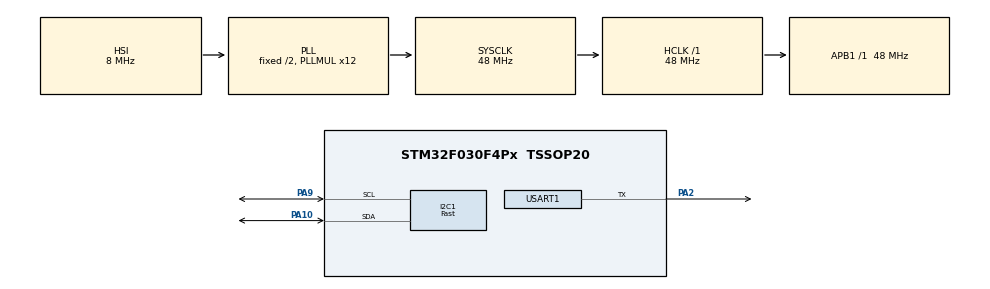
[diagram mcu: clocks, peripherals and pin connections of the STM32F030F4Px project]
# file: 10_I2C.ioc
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I2C1.Analog_Filter=I2C_ANALOGFILTER_DISABLE
I2C1.I2C_Speed_Mode=I2C_Fast
I2C1.Timing=0x0000020C
Mcu.Family=STM32F0
Mcu.Name=STM32F030F4Px
Mcu.Package=TSSOP20
PA10.Mode=I2C
PA10.Signal=I2C1_SDA
PA13.Mode=Serial_Wire
PA13.Signal=SYS_SWDIO
PA14.Mode=Serial_Wire
PA14.Signal=SYS_SWCLK
PA2.Mode=Half_duplex(single_wire_mode)
PA2.Signal=USART1_TX
PA9.Mode=I2C
PA9.Signal=I2C1_SCL
ProjectManager.HeapSize=0x200
ProjectManager.StackSize=0x400
ProjectManager.TargetToolchain=TrueSTUDIO
RCC.AHBFreq_Value=48000000
RCC.APB1Freq_Value=48000000
RCC.APB1TimFreq_Value=48000000
RCC.HCLKFreq_Value=48000000
RCC.PLLMUL=RCC_PLL_MUL12
RCC.SYSCLKFreq_VALUE=48000000
RCC.SYSCLKSource=RCC_SYSCLKSOURCE_PLLCLK
USART1.Mode=MODE_TX
USART1.VirtualMode-Half_duplex(single_wire_mode)=VM_ASYNC
board=10_I2C

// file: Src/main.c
/**
  ******************************************************************************
  * File Name          : main.c
  * Description        : Main program body
  ******************************************************************************
  ** This notice applies to any and all portions of this file
  * that are not between comment pairs USER CODE BEGIN and
  * USER CODE END. Other portions of this file, whether
  * inserted by the user or by software development tools
  * are owned by their respective copyright owners.
  *
  * COPYRIGHT(c) 2018 STMicroelectronics
  *
  * Redistribution and use in source and binary forms, with or without modification,
  * are permitted provided that the following conditions are met:
  *   1. Redistributions of source code must retain the above copyright notice,
  *      this list of conditions and the following disclaimer.
  *   2. Redistributions in binary form must reproduce the above copyright notice,
  *      this list of conditions and the following disclaimer in the documentation
  *      and/or other materials provided with the distribution.
  *   3. Neither the name of STMicroelectronics nor the names of its contributors
  *      may be used to endorse or promote products derived from this software
  *      without specific prior written permission.
  *
  * THIS SOFTWARE IS PROVIDED BY THE COPYRIGHT HOLDERS AND CONTRIBUTORS "AS IS"
  * AND ANY EXPRESS OR IMPLIED WARRANTIES, INCLUDING, BUT NOT LIMITED TO, THE
  * IMPLIED WARRANTIES OF MERCHANTABILITY AND FITNESS FOR A PARTICULAR PURPOSE ARE
  * DISCLAIMED. IN NO EVENT SHALL THE COPYRIGHT HOLDER OR CONTRIBUTORS BE LIABLE
  * FOR ANY DIRECT, INDIRECT, INCIDENTAL, SPECIAL, EXEMPLARY, OR CONSEQUENTIAL
  * DAMAGES (INCLUDING, BUT NOT LIMITED TO, PROCUREMENT OF SUBSTITUTE GOODS OR
  * SERVICES; LOSS OF USE, DATA, OR PROFITS; OR BUSINESS INTERRUPTION) HOWEVER
  * CAUSED AND ON ANY THEORY OF LIABILITY, WHETHER IN CONTRACT, STRICT LIABILITY,
  * OR TORT (INCLUDING NEGLIGENCE OR OTHERWISE) ARISING IN ANY WAY OUT OF THE USE
  * OF THIS SOFTWARE, EVEN IF ADVISED OF THE POSSIBILITY OF SUCH DAMAGE.
  *
  ******************************************************************************
  */
#include "main.h"
#include "stm32f0xx_hal.h"

/* USER CODE BEGIN Includes */
#include <string.h>
#include <stdio.h>
#include <stdlib.h>

/* USER CODE END Includes */

I2C_HandleTypeDef hi2c1;

UART_HandleTypeDef huart1;

/* USER CODE BEGIN PV */
/* Private variables ---------------------------------------------------------*/

/* USER CODE END PV */

void SystemClock_Config(void);
static void MX_GPIO_Init(void);
static void MX_I2C1_Init(void);
static void MX_USART1_UART_Init(void);

/* USER CODE BEGIN PFP */
/* Private function prototypes -----------------------------------------------*/
HAL_StatusTypeDef Write_To_24LCxx(I2C_HandleTypeDef *hi2c, uint16_t DevAddress, uint16_t MemAddress, uint8_t *pData, uint16_t len);
HAL_StatusTypeDef Read_From_24LCxx(I2C_HandleTypeDef *hi2c, uint16_t DevAddress, uint16_t MemAddress, uint8_t *pData, uint16_t len);

/* USER CODE END PFP */

int main(void)
{

  /* MCU Configuration----------------------------------------------------------*/

  /* Reset of all peripherals, Initializes the Flash interface and the Systick. */
  HAL_Init();

  /* Configure the system clock */
  SystemClock_Config();

  /* Initialize all configured peripherals */
  MX_GPIO_Init();
  MX_I2C1_Init();
  MX_USART1_UART_Init();

  /* USER CODE BEGIN 2 */

  // message for UART
  char msg[30];

  // Array for Write Message
  const char wmsg[] ="Hello I2C";

  // Array for Read Message, note must be exact size of Write Message
  char rmsg[10];

  /* USER CODE END 2 */

  /* Infinite loop */
  while (1)
  {

  /* USER CODE BEGIN 3 */
	 Write_To_24LCxx(&hi2c1, 0x50, 0x00, (uint8_t*)wmsg, strlen(wmsg)+1);
	 Read_From_24LCxx(&hi2c1, 0x50, 0x00, (uint8_t*)rmsg, strlen(wmsg)+1);

	 if(strcmp(wmsg, rmsg) == 0){
		 sprintf(msg, "Write Success!\n");
		 HAL_UART_Transmit(&huart1, (uint8_t*)msg, strlen(msg), HAL_MAX_DELAY);
		 sprintf(msg, "%s\n", rmsg);
		 HAL_UART_Transmit(&huart1, (uint8_t*)msg, strlen(msg), HAL_MAX_DELAY);
		 HAL_Delay(10000);
	 }

	 else
	 {
		sprintf(msg, "Write Failed, Read: %s\n", rmsg);
		HAL_UART_Transmit(&huart1, (uint8_t*)msg, strlen(msg), HAL_MAX_DELAY);
		HAL_Delay(10000);
	 }

  }
  /* USER CODE END 3 */

}

/** System Clock Configuration
*/
void SystemClock_Config(void)
{

  RCC_OscInitTypeDef RCC_OscInitStruct;
  RCC_ClkInitTypeDef RCC_ClkInitStruct;
  RCC_PeriphCLKInitTypeDef PeriphClkInit;

    /**Initializes the CPU, AHB and APB busses clocks
    */
  RCC_OscInitStruct.OscillatorType = RCC_OSCILLATORTYPE_HSI;
  RCC_OscInitStruct.HSIState = RCC_HSI_ON;
  RCC_OscInitStruct.HSICalibrationValue = 16;
  RCC_OscInitStruct.PLL.PLLState = RCC_PLL_ON;
  RCC_OscInitStruct.PLL.PLLSource = RCC_PLLSOURCE_HSI;
  RCC_OscInitStruct.PLL.PLLMUL = RCC_PLL_MUL12;
  RCC_OscInitStruct.PLL.PREDIV = RCC_PREDIV_DIV1;
  if (HAL_RCC_OscConfig(&RCC_OscInitStruct) != HAL_OK)
  {
    _Error_Handler(__FILE__, __LINE__);
  }

    /**Initializes the CPU, AHB and APB busses clocks
    */
  RCC_ClkInitStruct.ClockType = RCC_CLOCKTYPE_HCLK|RCC_CLOCKTYPE_SYSCLK
                              |RCC_CLOCKTYPE_PCLK1;
  RCC_ClkInitStruct.SYSCLKSource = RCC_SYSCLKSOURCE_PLLCLK;
  RCC_ClkInitStruct.AHBCLKDivider = RCC_SYSCLK_DIV1;
  RCC_ClkInitStruct.APB1CLKDivider = RCC_HCLK_DIV1;

  if (HAL_RCC_ClockConfig(&RCC_ClkInitStruct, FLASH_LATENCY_1) != HAL_OK)
  {
    _Error_Handler(__FILE__, __LINE__);
  }

  PeriphClkInit.PeriphClockSelection = RCC_PERIPHCLK_USART1|RCC_PERIPHCLK_I2C1;
  PeriphClkInit.Usart1ClockSelection = RCC_USART1CLKSOURCE_PCLK1;
  PeriphClkInit.I2c1ClockSelection = RCC_I2C1CLKSOURCE_HSI;
  if (HAL_RCCEx_PeriphCLKConfig(&PeriphClkInit) != HAL_OK)
  {
    _Error_Handler(__FILE__, __LINE__);
  }

    /**Configure the Systick interrupt time
    */
  HAL_SYSTICK_Config(HAL_RCC_GetHCLKFreq()/1000);

    /**Configure the Systick
    */
  HAL_SYSTICK_CLKSourceConfig(SYSTICK_CLKSOURCE_HCLK);

  /* SysTick_IRQn interrupt configuration */
  HAL_NVIC_SetPriority(SysTick_IRQn, 0, 0);
}

/* I2C1 init function */
static void MX_I2C1_Init(void)
{

  hi2c1.Instance = I2C1;
  hi2c1.Init.Timing = 0x0000020C;
  hi2c1.Init.OwnAddress1 = 0;
  hi2c1.Init.AddressingMode = I2C_ADDRESSINGMODE_7BIT;
  hi2c1.Init.DualAddressMode = I2C_DUALADDRESS_DISABLE;
  hi2c1.Init.OwnAddress2 = 0;
  hi2c1.Init.OwnAddress2Masks = I2C_OA2_NOMASK;
  hi2c1.Init.GeneralCallMode = I2C_GENERALCALL_DISABLE;
  hi2c1.Init.NoStretchMode = I2C_NOSTRETCH_DISABLE;
  if (HAL_I2C_Init(&hi2c1) != HAL_OK)
  {
    _Error_Handler(__FILE__, __LINE__);
  }

    /**Configure Analogue filter
    */
  if (HAL_I2CEx_ConfigAnalogFilter(&hi2c1, I2C_ANALOGFILTER_DISABLE) != HAL_OK)
  {
    _Error_Handler(__FILE__, __LINE__);
  }

    /**Configure Digital filter
    */
  if (HAL_I2CEx_ConfigDigitalFilter(&hi2c1, 0) != HAL_OK)
  {
    _Error_Handler(__FILE__, __LINE__);
  }

}

/* USART1 init function */
static void MX_USART1_UART_Init(void)
{

  huart1.Instance = USART1;
  huart1.Init.BaudRate = 38400;
  huart1.Init.WordLength = UART_WORDLENGTH_8B;
  huart1.Init.StopBits = UART_STOPBITS_1;
  huart1.Init.Parity = UART_PARITY_NONE;
  huart1.Init.Mode = UART_MODE_TX;
  huart1.Init.HwFlowCtl = UART_HWCONTROL_NONE;
  huart1.Init.OverSampling = UART_OVERSAMPLING_16;
  huart1.Init.OneBitSampling = UART_ONE_BIT_SAMPLE_DISABLE;
  huart1.AdvancedInit.AdvFeatureInit = UART_ADVFEATURE_NO_INIT;
  if (HAL_HalfDuplex_Init(&huart1) != HAL_OK)
  {
    _Error_Handler(__FILE__, __LINE__);
  }

}

/** Configure pins as
        * Analog
        * Input
        * Output
        * EVENT_OUT
        * EXTI
*/
static void MX_GPIO_Init(void)
{

  /* GPIO Ports Clock Enable */
  __HAL_RCC_GPIOA_CLK_ENABLE();

}

/* USER CODE BEGIN 4 */

HAL_StatusTypeDef Read_From_24LCxx(I2C_HandleTypeDef *hi2c, uint16_t DevAddress, uint16_t MemAddress, uint8_t *pData, uint16_t len) {
  HAL_StatusTypeDef returnValue;
  uint8_t addr[2];

  /* We compute the MSB and LSB parts of the memory address */
  addr[0] = (uint8_t) ((MemAddress & 0xFF00) >> 8);
  addr[1] = (uint8_t) (MemAddress & 0xFF);

  /* First we send the memory location address where start reading data */
  returnValue = HAL_I2C_Master_Transmit(hi2c, DevAddress, addr, 2, HAL_MAX_DELAY);
  if(returnValue != HAL_OK)
    return returnValue;

  /* Next we can retrieve the data from EEPROM */
  returnValue = HAL_I2C_Master_Receive(hi2c, DevAddress, pData, len, HAL_MAX_DELAY);

  return returnValue;
}

HAL_StatusTypeDef Write_To_24LCxx(I2C_HandleTypeDef *hi2c, uint16_t DevAddress, uint16_t MemAddress, uint8_t *pData, uint16_t len) {
  HAL_StatusTypeDef returnValue;
  uint8_t *data;

  /* First we allocate a temporary buffer to store the destination memory
   * address and the data to store */
  data = (uint8_t*)malloc(sizeof(uint8_t)*(len+2));

  /* We compute the MSB and LSB parts of the memory address */
  data[0] = (uint8_t) ((MemAddress & 0xFF00) >> 8);
  data[1] = (uint8_t) (MemAddress & 0xFF);

  /* And copy the content of the pData array in the temporary buffer */
  memcpy(data+2, pData, len);

  /* We are now ready to transfer the buffer over the I2C bus */
  returnValue = HAL_I2C_Master_Transmit(hi2c, DevAddress, data, len + 2, HAL_MAX_DELAY);
  if(returnValue != HAL_OK)
    return returnValue;

  free(data);

  /* We wait until the EEPROM effectively stores data in memory.
   * The technique shown in the book doesn't work here, due some
   * limitations of the I2C peripheral in STM32F1 devices. We
   * so use the dedicated HAL routine.
   */
  while(HAL_I2C_IsDeviceReady(hi2c, DevAddress, 1, HAL_MAX_DELAY) != HAL_OK);

  return HAL_OK;
}

/* USER CODE END 4 */

void _Error_Handler(char * file, int line)
{
  while(1)
  {
  }
}

/************************ (C) COPYRIGHT STMicroelectronics *****END OF FILE****/
